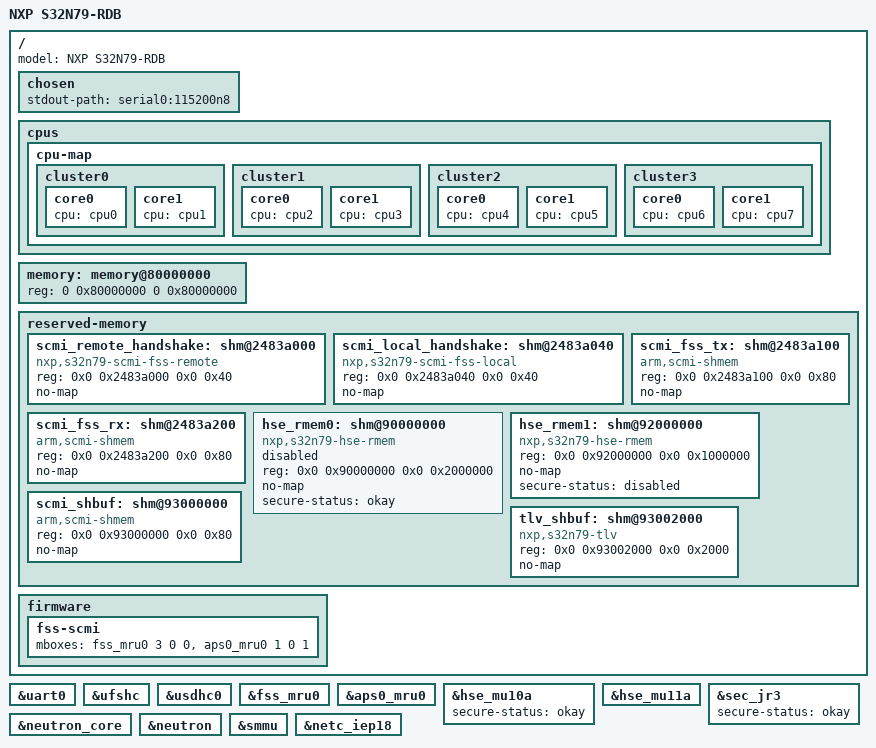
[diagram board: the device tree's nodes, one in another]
// SPDX-License-Identifier: (GPL-2.0+ OR BSD-3-Clause)
/*
 * Copyright 2025-2026 NXP
 */

/dts-v1/;
#include "s32n79-rdb.dtsi"

/ {
	model = "NXP S32N79-RDB";

	chosen {
		stdout-path = "serial0:115200n8";
	};

	cpus {
		cpu-map {
			cluster0 {
				core0 {
					cpu = <&cpu0>;
				};

				core1 {
					cpu = <&cpu1>;
				};
			};

			cluster1 {
				core0 {
					cpu = <&cpu2>;
				};

				core1 {
					cpu = <&cpu3>;
				};
			};

			cluster2 {
				core0 {
					cpu = <&cpu4>;
				};

				core1 {
					cpu = <&cpu5>;
				};
			};

			cluster3 {
				core0 {
					cpu = <&cpu6>;
				};

				core1 {
					cpu = <&cpu7>;
				};
			};
		};
	};

	memory: memory@80000000 {
		device_type = "memory";
		reg = <0 0x80000000 0 0x80000000>;
	};

	reserved-memory {
		#address-cells = <2>;
		#size-cells = <2>;
		ranges;

		scmi_remote_handshake: shm@2483a000 {
			compatible = "nxp,s32n79-scmi-fss-remote";
			reg = <0x0 0x2483a000 0x0 0x40>;
			no-map;
		};

		scmi_local_handshake: shm@2483a040 {
			compatible = "nxp,s32n79-scmi-fss-local";
			reg = <0x0 0x2483a040 0x0 0x40>;
			no-map;
		};

		/* FSS SCMI TX Mailbox */
		scmi_fss_tx: shm@2483a100 {
			compatible = "arm,scmi-shmem";
			reg = <0x0 0x2483a100 0x0 0x80>;
			no-map;
		};

		/* FSS SCMI RX Mailbox */
		scmi_fss_rx: shm@2483a200 {
			compatible = "arm,scmi-shmem";
			reg = <0x0 0x2483a200 0x0 0x80>;
			no-map;
		};

		hse_rmem0: shm@90000000 {
			compatible = "nxp,s32n79-hse-rmem";
			reg = <0x0 0x90000000 0x0 0x2000000>; /* 32 MB */
			no-map;
			status = "disabled";
			secure-status = "okay";
		};

		hse_rmem1: shm@92000000 {
			compatible = "nxp,s32n79-hse-rmem";
			reg = <0x0 0x92000000 0x0 0x1000000>; /* 16 MB */
			no-map;
			status = "okay";
			secure-status = "disabled";
		};

		scmi_shbuf: shm@93000000 {
			compatible = "arm,scmi-shmem";
			reg = <0x0 0x93000000 0x0 0x80>;
			no-map;
		};

		tlv_shbuf: shm@93002000 {
			compatible = "nxp,s32n79-tlv";
			reg = <0x0 0x93002000 0x0 0x2000>;
			no-map;
		};
	};

	firmware {
		fss-scmi {
			/*
			 * mru instance, chan, mailbox, tx/rx
			 * type: SCMI_TX -> 0
			 * type: SCMI_RX -> 1
			 */
			mboxes = <&fss_mru0 3 0 0>, <&aps0_mru0 1 0 1>;
		};
	};
};

&uart0 {
	status = "okay";
};

&ufshc {
	status = "okay";
};

&usdhc0 {
	status = "okay";
};

&fss_mru0 {
	status = "okay";
};

&aps0_mru0 {
	status = "okay";
};

&hse_mu10a {
	secure-status = "okay";
};

&hse_mu11a {
	status = "okay";
};

&sec_jr3 {
	secure-status = "okay";
};

&neutron_core {
	status = "okay";
};

&neutron {
	status = "okay";
};

&smmu {
	status = "okay";
};

&netc_iep18 {
	status = "okay";
};
